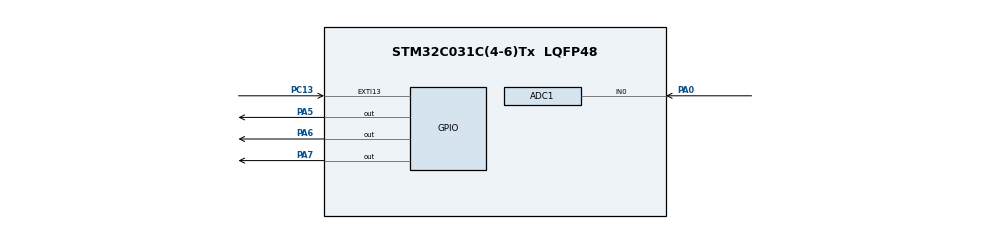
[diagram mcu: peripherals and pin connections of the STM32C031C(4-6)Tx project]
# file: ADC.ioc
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ADC1.NbrOfConversion=1
ADC1.NbrOfConversionFlag=0
ADC1.SelectedChannel=ADC_CHANNEL_0
ADC1.master=1
Mcu.Family=STM32C0
Mcu.Name=STM32C031C(4-6)Tx
Mcu.Package=LQFP48
NUCLEO-C031C6.BUTTON=1
NUCLEO-C031C6.LD4=true
NUCLEO-C031C6.VCP=true
NVIC.EXTI4_15_IRQn=true\:0\:0\:false\:false\:true\:true\:true\:true
PA0.Mode=IN0
PA0.Signal=ADC1_IN0
PA13.GPIO_Label=DEBUG_SWDIO
PA13.Signal=DEBUG_SWDIO
PA14-BOOT0.GPIO_Label=DEBUG_SWCLK
PA14-BOOT0.Signal=DEBUG_SWCLK
PA2.Signal=USART2_TX
PA3.Signal=USART2_RX
PA5.Signal=GPIO_Output
PA6.Signal=GPIO_Output
PA7.Signal=GPIO_Output
PC13.Signal=GPXTI13
PC14-OSCX_IN\ (PC14).GPIO_Label=RCC_OSCX_IN
PC14-OSCX_IN\ (PC14).Mode=LSE-External-Oscillator
PC14-OSCX_IN\ (PC14).Signal=RCC_OSCX_IN
PC15-OSCX_OUT\ (PC15).GPIO_Label=RCC_OSCX_OUT
PC15-OSCX_OUT\ (PC15).Mode=LSE-External-Oscillator
PC15-OSCX_OUT\ (PC15).Signal=RCC_OSCX_OUT
PF0-OSC_IN\ (PF0).GPIO_Label=RCC_OSC_IN
PF0-OSC_IN\ (PF0).Mode=HSE-External-Oscillator
PF0-OSC_IN\ (PF0).Signal=RCC_OSC_IN
PF1-OSC_OUT\ (PF1).GPIO_Label=RCC_OSC_OUT
PF1-OSC_OUT\ (PF1).Mode=HSE-External-Oscillator
PF1-OSC_OUT\ (PF1).Signal=RCC_OSC_OUT
ProjectManager.HeapSize=0x200
ProjectManager.StackSize=0x400
ProjectManager.TargetToolchain=Makefile
RCC.ADCFreq_Value=48000000
RCC.AHBFreq_Value=48000000
RCC.CortexFreq_Value=48000000
RCC.EXTERNAL_CLOCK_VALUE=12288000
RCC.HCLKFreq_Value=48000000
RCC.HSE_VALUE=48000000
RCC.HSISYSCLKDivider=RCC_HSI_DIV1
RCC.HSI_VALUE=48000000
RCC.SYSCLKFreq_VALUE=48000000
RCC.SYSCLKSource=RCC_SYSCLKSOURCE_HSE
VP_NUCLEO-C031C6_VS_BSP_COMMON.Mode=COMMON
board=NUCLEO-C031C6

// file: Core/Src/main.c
/* USER CODE BEGIN Header */
/**
  ******************************************************************************
  * @file           : main.c
  * @brief          : Main program body
  ******************************************************************************
  * @attention
  *
  * Copyright (c) 2025 STMicroelectronics.
  * All rights reserved.
  *
  * This software is licensed under terms that can be found in the LICENSE file
  * in the root directory of this software component.
  * If no LICENSE file comes with this software, it is provided AS-IS.
  *
  ******************************************************************************
  */
/* USER CODE END Header */
#include "main.h"

COM_InitTypeDef BspCOMInit;
ADC_HandleTypeDef hadc1;

void SystemClock_Config(void);
static void MX_GPIO_Init(void);
static void MX_ADC1_Init(void);
/* USER CODE BEGIN PFP */
uint16_t adcValue;//adc addition
/* USER CODE END PFP */

int main(void)
{

  /* MCU Configuration--------------------------------------------------------*/

  /* Reset of all peripherals, Initializes the Flash interface and the Systick. */
  HAL_Init();

  /* Configure the system clock */
  SystemClock_Config();

  /* Initialize all configured peripherals */
  MX_GPIO_Init();
  MX_ADC1_Init();

  /* Initialize leds */
  BSP_LED_Init(LED_GREEN);

  /* Initialize USER push-button, will be used to trigger an interrupt each time it's pressed.*/
  BSP_PB_Init(BUTTON_USER, BUTTON_MODE_EXTI);

  /* Initialize COM1 port (115200, 8 bits (7-bit data + 1 stop bit), no parity */
  BspCOMInit.BaudRate   = 115200;
  BspCOMInit.WordLength = COM_WORDLENGTH_8B;
  BspCOMInit.StopBits   = COM_STOPBITS_1;
  BspCOMInit.Parity     = COM_PARITY_NONE;
  BspCOMInit.HwFlowCtl  = COM_HWCONTROL_NONE;
  if (BSP_COM_Init(COM1, &BspCOMInit) != BSP_ERROR_NONE)
  {
    Error_Handler();
  }

  /* Infinite loop */
  /* USER CODE BEGIN WHILE */
  while (1)
  {
    HAL_ADC_Start(&hadc1);
    HAL_ADC_PollForConversion(&hadc1, 100);
    adcValue = HAL_ADC_GetValue(&hadc1);
    HAL_ADC_Stop(&hadc1);

    if (adcValue >= 512)
    {
        HAL_GPIO_WritePin(GPIOA, GPIO_PIN_5, GPIO_PIN_SET);
        HAL_GPIO_WritePin(GPIOA, GPIO_PIN_6, GPIO_PIN_RESET);
    }
    else
    {
        HAL_GPIO_WritePin(GPIOA, GPIO_PIN_5, GPIO_PIN_RESET);
        HAL_GPIO_WritePin(GPIOA, GPIO_PIN_6, GPIO_PIN_SET);
    }
	}
    /* USER CODE END WHILE */

}

void SystemClock_Config(void)
{
  RCC_OscInitTypeDef RCC_OscInitStruct = {0};
  RCC_ClkInitTypeDef RCC_ClkInitStruct = {0};

  /** Initializes the RCC Oscillators according to the specified parameters
  * in the RCC_OscInitTypeDef structure.
  */
  RCC_OscInitStruct.OscillatorType = RCC_OSCILLATORTYPE_HSE;
  RCC_OscInitStruct.HSEState = RCC_HSE_ON;
  if (HAL_RCC_OscConfig(&RCC_OscInitStruct) != HAL_OK)
  {
    Error_Handler();
  }

  /** Initializes the CPU, AHB and APB buses clocks
  */
  RCC_ClkInitStruct.ClockType = RCC_CLOCKTYPE_HCLK|RCC_CLOCKTYPE_SYSCLK
                              |RCC_CLOCKTYPE_PCLK1;
  RCC_ClkInitStruct.SYSCLKSource = RCC_SYSCLKSOURCE_HSE;
  RCC_ClkInitStruct.SYSCLKDivider = RCC_SYSCLK_DIV1;
  RCC_ClkInitStruct.AHBCLKDivider = RCC_HCLK_DIV1;
  RCC_ClkInitStruct.APB1CLKDivider = RCC_APB1_DIV1;

  if (HAL_RCC_ClockConfig(&RCC_ClkInitStruct, FLASH_LATENCY_1) != HAL_OK)
  {
    Error_Handler();
  }
}

static void MX_ADC1_Init(void)
{

  ADC_ChannelConfTypeDef sConfig = {0};
  /** Configure the global features of the ADC (Clock, Resolution, Data Alignment and number of conversion)
  */
  hadc1.Instance = ADC1;
  hadc1.Init.ClockPrescaler = ADC_CLOCK_SYNC_PCLK_DIV2;
  hadc1.Init.Resolution = ADC_RESOLUTION_12B;
  hadc1.Init.DataAlign = ADC_DATAALIGN_RIGHT;
  hadc1.Init.ScanConvMode = ADC_SCAN_SEQ_FIXED;
  hadc1.Init.EOCSelection = ADC_EOC_SINGLE_CONV;
  hadc1.Init.LowPowerAutoWait = DISABLE;
  hadc1.Init.LowPowerAutoPowerOff = DISABLE;
  hadc1.Init.ContinuousConvMode = DISABLE;
  hadc1.Init.NbrOfConversion = 1;
  hadc1.Init.DiscontinuousConvMode = DISABLE;
  hadc1.Init.ExternalTrigConv = ADC_SOFTWARE_START;
  hadc1.Init.ExternalTrigConvEdge = ADC_EXTERNALTRIGCONVEDGE_NONE;
  hadc1.Init.DMAContinuousRequests = DISABLE;
  hadc1.Init.Overrun = ADC_OVR_DATA_PRESERVED;
  hadc1.Init.SamplingTimeCommon1 = ADC_SAMPLETIME_1CYCLE_5;
  hadc1.Init.OversamplingMode = DISABLE;
  hadc1.Init.TriggerFrequencyMode = ADC_TRIGGER_FREQ_HIGH;
  if (HAL_ADC_Init(&hadc1) != HAL_OK)
  {
    Error_Handler();
  }

  /** Configure Regular Channel
  */
  sConfig.Channel = ADC_CHANNEL_0;
  sConfig.Rank = ADC_RANK_CHANNEL_NUMBER;
  if (HAL_ADC_ConfigChannel(&hadc1, &sConfig) != HAL_OK)
  {
    Error_Handler();
  }

}

static void MX_GPIO_Init(void)
{
  GPIO_InitTypeDef GPIO_InitStruct = {0};

  /* GPIO Ports Clock Enable */
  __HAL_RCC_GPIOC_CLK_ENABLE();
  __HAL_RCC_GPIOF_CLK_ENABLE();
  __HAL_RCC_GPIOA_CLK_ENABLE();

  /*Configure GPIO pin Output Level */
  HAL_GPIO_WritePin(GPIOA, GPIO_PIN_5|GPIO_PIN_6|GPIO_PIN_7, GPIO_PIN_RESET);

  /*Configure GPIO pins : PA5 PA6 PA7 */
  GPIO_InitStruct.Pin = GPIO_PIN_5|GPIO_PIN_6|GPIO_PIN_7;
  GPIO_InitStruct.Mode = GPIO_MODE_OUTPUT_PP;
  GPIO_InitStruct.Pull = GPIO_NOPULL;
  GPIO_InitStruct.Speed = GPIO_SPEED_FREQ_LOW;
  HAL_GPIO_Init(GPIOA, &GPIO_InitStruct);

}

void Error_Handler(void)
{
  __disable_irq();
  while (1)
  {
  }
}
